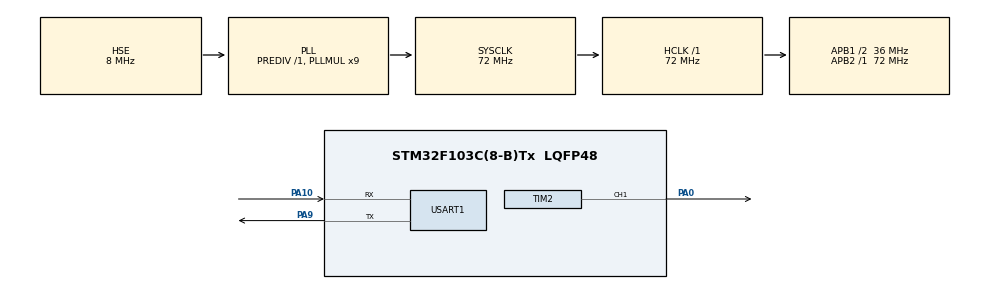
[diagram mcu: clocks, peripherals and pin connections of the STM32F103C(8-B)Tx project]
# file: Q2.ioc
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Mcu.Family=STM32F1
Mcu.Name=STM32F103C(8-B)Tx
Mcu.Package=LQFP48
NVIC.PriorityGroup=NVIC_PRIORITYGROUP_4
PA0-WKUP.Signal=S_TIM2_CH1_ETR
PA10.Mode=Asynchronous
PA10.Signal=USART1_RX
PA13.Mode=Serial_Wire
PA13.Signal=SYS_JTMS-SWDIO
PA14.Mode=Serial_Wire
PA14.Signal=SYS_JTCK-SWCLK
PA9.Mode=Asynchronous
PA9.Signal=USART1_TX
PD0-OSC_IN.Mode=HSE-External-Oscillator
PD0-OSC_IN.Signal=RCC_OSC_IN
PD1-OSC_OUT.Mode=HSE-External-Oscillator
PD1-OSC_OUT.Signal=RCC_OSC_OUT
ProjectManager.HeapSize=0x200
ProjectManager.StackSize=0x400
ProjectManager.TargetToolchain=CMake
RCC.AHBFreq_Value=72000000
RCC.APB1CLKDivider=RCC_HCLK_DIV2
RCC.APB1Freq_Value=36000000
RCC.APB1TimFreq_Value=72000000
RCC.APB2Freq_Value=72000000
RCC.APB2TimFreq_Value=72000000
RCC.HCLKFreq_Value=72000000
RCC.PLLMUL=RCC_PLL_MUL9
RCC.PLLSourceVirtual=RCC_PLLSOURCE_HSE
RCC.SYSCLKFreq_VALUE=72000000
RCC.SYSCLKSource=RCC_SYSCLKSOURCE_PLLCLK
RCC.USBFreq_Value=72000000
SH.S_TIM2_CH1_ETR.0=TIM2_CH1,PWM Generation1 CH1
TIM2.Channel-PWM\ Generation1\ CH1=TIM_CHANNEL_1
TIM2.Period=19999
TIM2.Prescaler=71
USART1.VirtualMode=VM_ASYNC
board=custom

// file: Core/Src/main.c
/* USER CODE BEGIN Header */
/**
  ******************************************************************************
  * @file           : main.c
  * @brief          : Main program body
  ******************************************************************************
  * @attention
  *
  * Copyright (c) 2026 STMicroelectronics.
  * All rights reserved.
  *
  * This software is licensed under terms that can be found in the LICENSE file
  * in the root directory of this software component.
  * If no LICENSE file comes with this software, it is provided AS-IS.
  *
  ******************************************************************************
  */
/* USER CODE END Header */
#include "main.h"

/* USER CODE BEGIN Includes */
#include <stdlib.h>

/* USER CODE END Includes */

TIM_HandleTypeDef htim2;

UART_HandleTypeDef huart1;

/* USER CODE BEGIN PV */
uint8_t rx_byte = 0;
char angle_buffer[4] = {0};
uint8_t angle_index = 0;
uint16_t current_angle = 90;
uint32_t current_pulse = 1500;
uint32_t last_report_tick = 0;

/* USER CODE END PV */

void SystemClock_Config(void);
static void MX_GPIO_Init(void);
static void MX_TIM2_Init(void);
static void MX_USART1_UART_Init(void);
/* USER CODE BEGIN PFP */
static void Servo_SetAngle(uint16_t angle);
static void VOFA_SendJustFloat(void);           //JustFloat 函数声明

/* USER CODE END PFP */

/* USER CODE BEGIN 0 */
static void Servo_SetAngle(uint16_t angle)
{
  if (angle > 180)
  {
    angle = 180;
  }

  uint32_t pulse;

  pulse = 500 + ((uint32_t)angle * 2000) / 180;

  __HAL_TIM_SET_COMPARE(&htim2, TIM_CHANNEL_1, pulse);

  current_angle = angle;
  current_pulse = pulse;
}
static void VOFA_SendJustFloat(void)
{
  float data[2];

  uint8_t tail[4] =
  {
    0x00, 0x00, 0x80, 0x7F
  };

  //第1路数据：舵机角度
  data[0] = (float)current_angle;

  //第2路数据：PWM占空比
  data[1] = ((float)current_pulse / 20000.0f) * 100.0f;

  HAL_UART_Transmit(
      &huart1,
      (uint8_t *)data,
      sizeof(data),
      100
  );

  //JustFloat固定帧尾
  HAL_UART_Transmit(
      &huart1,
      tail,
      sizeof(tail),
      100
  );
}
/* USER CODE END 0 */

int main(void)
{

  /* MCU Configuration--------------------------------------------------------*/

  /* Reset of all peripherals, Initializes the Flash interface and the Systick. */
  HAL_Init();

  /* Configure the system clock */
  SystemClock_Config();

  /* Initialize all configured peripherals */
  MX_GPIO_Init();
  MX_TIM2_Init();
  MX_USART1_UART_Init();
  /* USER CODE BEGIN 2 */
  HAL_TIM_PWM_Start(&htim2, TIM_CHANNEL_1);
  Servo_SetAngle(90);
  /* USER CODE END 2 */

  /* Infinite loop */
  while (1) {

    /* USER CODE BEGIN 3 */
    //接收目标角度
    if (HAL_UART_Receive(&huart1, &rx_byte, 1, 10) == HAL_OK)
    {
      if (rx_byte >= '0' && rx_byte <= '9')
      {
        if (angle_index < sizeof(angle_buffer) - 1)
        {
          angle_buffer[angle_index++] = rx_byte;
        }
      }
      else if ((rx_byte == '\r' || rx_byte == '\n') &&
               angle_index > 0)
      {
        angle_buffer[angle_index] = '\0';

        int angle = atoi(angle_buffer);

        if (angle >= 0 && angle <= 180)
        {
          Servo_SetAngle((uint16_t)angle);
        }

        angle_index = 0;
      }
      else
      {
        angle_index = 0;
      }
    }

    //每100ms发送一次JustFloat
    if (HAL_GetTick() - last_report_tick >= 100)
    {
      last_report_tick = HAL_GetTick();

      VOFA_SendJustFloat();
    }
  }
  /* USER CODE END 3 */
}

void SystemClock_Config(void)
{
  RCC_OscInitTypeDef RCC_OscInitStruct = {0};
  RCC_ClkInitTypeDef RCC_ClkInitStruct = {0};

  /** Initializes the RCC Oscillators according to the specified parameters
  * in the RCC_OscInitTypeDef structure.
  */
  RCC_OscInitStruct.OscillatorType = RCC_OSCILLATORTYPE_HSE;
  RCC_OscInitStruct.HSEState = RCC_HSE_ON;
  RCC_OscInitStruct.HSEPredivValue = RCC_HSE_PREDIV_DIV1;
  RCC_OscInitStruct.HSIState = RCC_HSI_ON;
  RCC_OscInitStruct.PLL.PLLState = RCC_PLL_ON;
  RCC_OscInitStruct.PLL.PLLSource = RCC_PLLSOURCE_HSE;
  RCC_OscInitStruct.PLL.PLLMUL = RCC_PLL_MUL9;
  if (HAL_RCC_OscConfig(&RCC_OscInitStruct) != HAL_OK)
  {
    Error_Handler();
  }

  /** Initializes the CPU, AHB and APB buses clocks
  */
  RCC_ClkInitStruct.ClockType = RCC_CLOCKTYPE_HCLK|RCC_CLOCKTYPE_SYSCLK
                              |RCC_CLOCKTYPE_PCLK1|RCC_CLOCKTYPE_PCLK2;
  RCC_ClkInitStruct.SYSCLKSource = RCC_SYSCLKSOURCE_PLLCLK;
  RCC_ClkInitStruct.AHBCLKDivider = RCC_SYSCLK_DIV1;
  RCC_ClkInitStruct.APB1CLKDivider = RCC_HCLK_DIV2;
  RCC_ClkInitStruct.APB2CLKDivider = RCC_HCLK_DIV1;

  if (HAL_RCC_ClockConfig(&RCC_ClkInitStruct, FLASH_LATENCY_2) != HAL_OK)
  {
    Error_Handler();
  }
}

static void MX_TIM2_Init(void)
{

  TIM_MasterConfigTypeDef sMasterConfig = {0};
  TIM_OC_InitTypeDef sConfigOC = {0};

  htim2.Instance = TIM2;
  htim2.Init.Prescaler = 71;
  htim2.Init.CounterMode = TIM_COUNTERMODE_UP;
  htim2.Init.Period = 19999;
  htim2.Init.ClockDivision = TIM_CLOCKDIVISION_DIV1;
  htim2.Init.AutoReloadPreload = TIM_AUTORELOAD_PRELOAD_DISABLE;
  if (HAL_TIM_PWM_Init(&htim2) != HAL_OK)
  {
    Error_Handler();
  }
  sMasterConfig.MasterOutputTrigger = TIM_TRGO_RESET;
  sMasterConfig.MasterSlaveMode = TIM_MASTERSLAVEMODE_DISABLE;
  if (HAL_TIMEx_MasterConfigSynchronization(&htim2, &sMasterConfig) != HAL_OK)
  {
    Error_Handler();
  }
  sConfigOC.OCMode = TIM_OCMODE_PWM1;
  sConfigOC.Pulse = 0;
  sConfigOC.OCPolarity = TIM_OCPOLARITY_HIGH;
  sConfigOC.OCFastMode = TIM_OCFAST_DISABLE;
  if (HAL_TIM_PWM_ConfigChannel(&htim2, &sConfigOC, TIM_CHANNEL_1) != HAL_OK)
  {
    Error_Handler();
  }
  HAL_TIM_MspPostInit(&htim2);

}

static void MX_USART1_UART_Init(void)
{

  huart1.Instance = USART1;
  huart1.Init.BaudRate = 115200;
  huart1.Init.WordLength = UART_WORDLENGTH_8B;
  huart1.Init.StopBits = UART_STOPBITS_1;
  huart1.Init.Parity = UART_PARITY_NONE;
  huart1.Init.Mode = UART_MODE_TX_RX;
  huart1.Init.HwFlowCtl = UART_HWCONTROL_NONE;
  huart1.Init.OverSampling = UART_OVERSAMPLING_16;
  if (HAL_UART_Init(&huart1) != HAL_OK)
  {
    Error_Handler();
  }

}

static void MX_GPIO_Init(void)
{

  /* GPIO Ports Clock Enable */
  __HAL_RCC_GPIOD_CLK_ENABLE();
  __HAL_RCC_GPIOA_CLK_ENABLE();

}

void Error_Handler(void)
{
  __disable_irq();
  while (1)
  {
  }
}
